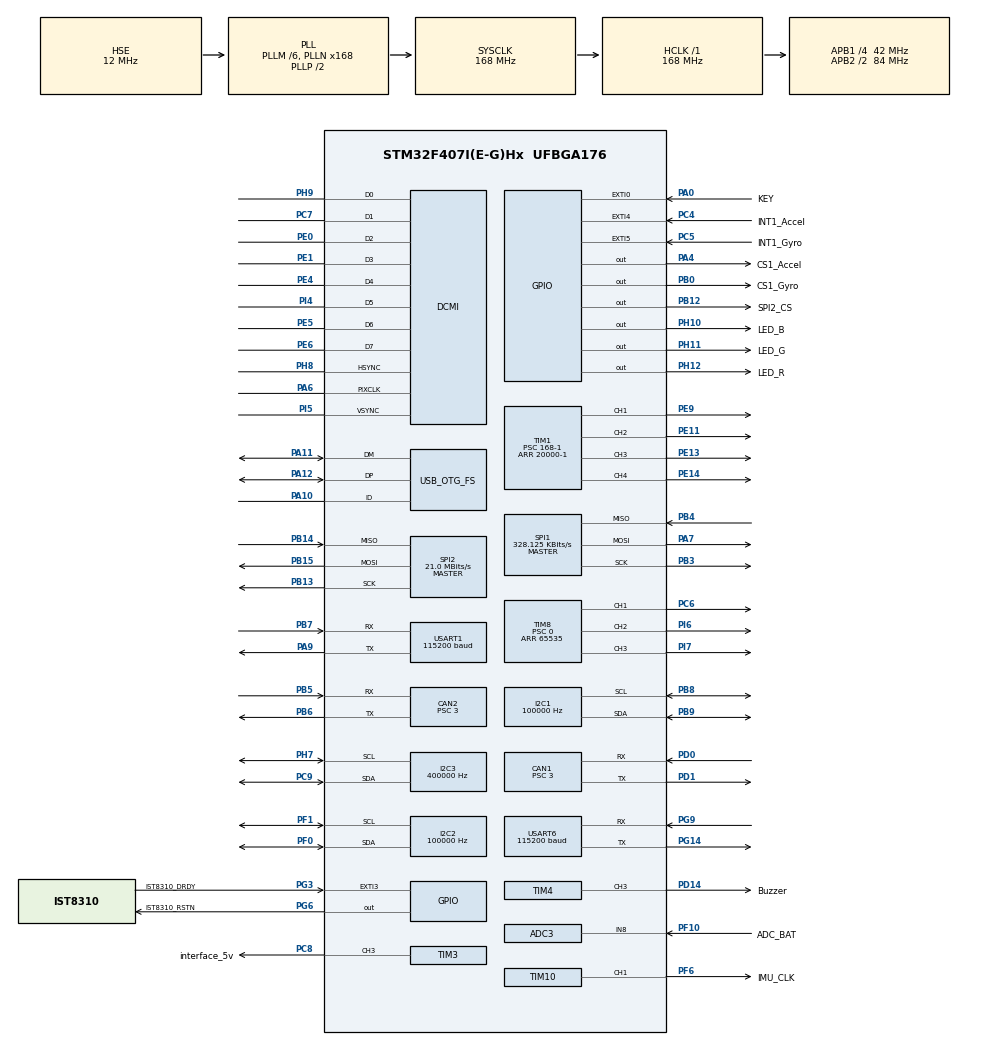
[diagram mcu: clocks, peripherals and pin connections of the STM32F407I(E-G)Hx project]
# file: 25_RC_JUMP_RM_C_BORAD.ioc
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ADC1.Channel-2\#ChannelRegularConversion=ADC_CHANNEL_TEMPSENSOR
ADC1.Channel-IN=ADC_CHANNEL_VREFINT
ADC1.ClockPrescaler=ADC_CLOCK_SYNC_PCLK_DIV4
ADC1.ContinuousConvMode=DISABLE
ADC1.DMAContinuousRequests=DISABLE
ADC1.DataAlign=ADC_DATAALIGN_RIGHT
ADC1.DiscontinuousConvMode=DISABLE
ADC1.EOCSelection=ADC_EOC_SINGLE_CONV
ADC1.EnableAnalogWatchDog=false
ADC1.ExternalTrigConv=ADC_SOFTWARE_START
ADC1.ExternalTrigConvEdge=ADC_EXTERNALTRIGCONVEDGE_NONE
ADC1.InjNumberOfConversion=0
ADC1.Mode=__NULL
ADC1.NbrOfConversion=1
ADC1.Rank-2\#ChannelRegularConversion=1
ADC1.Resolution=ADC_RESOLUTION_12B
ADC1.SamplingTime-2\#ChannelRegularConversion=ADC_SAMPLETIME_3CYCLES
ADC1.ScanConvMode=DISABLE
ADC1.master=1
ADC3.Channel-3\#ChannelRegularConversion=ADC_CHANNEL_8
ADC3.Channel-IN8=ADC_CHANNEL_8
ADC3.ClockPrescaler=ADC_CLOCK_SYNC_PCLK_DIV4
ADC3.ContinuousConvMode=DISABLE
ADC3.DMAContinuousRequests=DISABLE
ADC3.DataAlign=ADC_DATAALIGN_RIGHT
ADC3.DiscontinuousConvMode=DISABLE
ADC3.EOCSelection=ADC_EOC_SINGLE_CONV
ADC3.EnableAnalogWatchDog=false
ADC3.ExternalTrigConv=ADC_SOFTWARE_START
ADC3.ExternalTrigConvEdge=ADC_EXTERNALTRIGCONVEDGE_NONE
ADC3.InjNumberOfConversion=0
ADC3.NbrOfConversion=1
ADC3.Rank-3\#ChannelRegularConversion=1
ADC3.Resolution=ADC_RESOLUTION_12B
ADC3.SamplingTime-3\#ChannelRegularConversion=ADC_SAMPLETIME_3CYCLES
ADC3.ScanConvMode=DISABLE
CAN1.ABOM=DISABLE
CAN1.AWUM=DISABLE
CAN1.BS1=CAN_BS1_10TQ
CAN1.BS2=CAN_BS2_3TQ
CAN1.CalculateBaudRate=1000000
CAN1.CalculateTimeBit=1000
CAN1.CalculateTimeQuantum=71.42857142857143
CAN1.Mode=CAN_MODE_NORMAL
CAN1.NART=DISABLE
CAN1.Prescaler=3
CAN1.RFLM=DISABLE
CAN1.SJW=CAN_SJW_1TQ
CAN1.TTCM=DISABLE
CAN1.TXFP=DISABLE
CAN2.ABOM=DISABLE
CAN2.AWUM=DISABLE
CAN2.BS1=CAN_BS1_10TQ
CAN2.BS2=CAN_BS2_3TQ
CAN2.CalculateBaudRate=1000000
CAN2.CalculateTimeBit=1000
CAN2.CalculateTimeQuantum=71.42857142857143
CAN2.Mode=CAN_MODE_NORMAL
CAN2.NART=DISABLE
CAN2.Prescaler=3
CAN2.RFLM=DISABLE
CAN2.SJW=CAN_SJW_1TQ
CAN2.TTCM=DISABLE
CAN2.TXFP=DISABLE
DCMI.CaptureRate=DCMI_CR_ALL_FRAME
DCMI.HSPolarity=DCMI_HSPOLARITY_LOW
DCMI.JPEGMode=DCMI_JPEG_DISABLE
DCMI.PCKPolarity=DCMI_PCKPOLARITY_FALLING
DCMI.VSPolarity=DCMI_VSPOLARITY_LOW
Dma.Request0=SPI1_RX
Dma.Request1=SPI1_TX
Dma.SPI1_RX.0.Direction=DMA_PERIPH_TO_MEMORY
Dma.SPI1_RX.0.FIFOMode=DMA_FIFOMODE_DISABLE
Dma.SPI1_RX.0.Instance=DMA2_Stream2
Dma.SPI1_RX.0.MemDataAlignment=DMA_MDATAALIGN_BYTE
Dma.SPI1_RX.0.MemInc=DMA_MINC_ENABLE
Dma.SPI1_RX.0.Mode=DMA_NORMAL
Dma.SPI1_RX.0.PeriphDataAlignment=DMA_PDATAALIGN_BYTE
Dma.SPI1_RX.0.PeriphInc=DMA_PINC_DISABLE
Dma.SPI1_RX.0.Priority=DMA_PRIORITY_VERY_HIGH
Dma.SPI1_TX.1.Direction=DMA_MEMORY_TO_PERIPH
Dma.SPI1_TX.1.FIFOMode=DMA_FIFOMODE_DISABLE
Dma.SPI1_TX.1.Instance=DMA2_Stream3
Dma.SPI1_TX.1.MemDataAlignment=DMA_MDATAALIGN_BYTE
Dma.SPI1_TX.1.MemInc=DMA_MINC_ENABLE
Dma.SPI1_TX.1.Mode=DMA_NORMAL
Dma.SPI1_TX.1.PeriphDataAlignment=DMA_PDATAALIGN_BYTE
Dma.SPI1_TX.1.PeriphInc=DMA_PINC_DISABLE
Dma.SPI1_TX.1.Priority=DMA_PRIORITY_HIGH
I2C1.AddressingMode=I2C_ADDRESSINGMODE_7BIT
I2C1.ClockSpeed=100000
I2C1.DualAddressMode=I2C_DUALADDRESS_DISABLE
I2C1.GeneralCallMode=I2C_GENERALCALL_DISABLE
I2C1.I2C_Mode=I2C_Standard
I2C1.NoStretchMode=I2C_NOSTRETCH_DISABLE
I2C1.OwnAddress=0
I2C2.AddressingMode=I2C_ADDRESSINGMODE_7BIT
I2C2.ClockSpeed=100000
I2C2.DualAddressMode=I2C_DUALADDRESS_DISABLE
I2C2.GeneralCallMode=I2C_GENERALCALL_DISABLE
I2C2.I2C_Mode=I2C_Standard
I2C2.NoStretchMode=I2C_NOSTRETCH_DISABLE
I2C2.OwnAddress=0
I2C3.AddressingMode=I2C_ADDRESSINGMODE_7BIT
I2C3.ClockSpeed=400000
I2C3.DualAddressMode=I2C_DUALADDRESS_DISABLE
I2C3.DutyCycle=I2C_DUTYCYCLE_2
I2C3.GeneralCallMode=I2C_GENERALCALL_DISABLE
I2C3.I2C_Mode=I2C_Fast
I2C3.NoStretchMode=I2C_NOSTRETCH_DISABLE
I2C3.OwnAddress=0
Mcu.Family=STM32F4
Mcu.Name=STM32F407I(E-G)Hx
Mcu.Package=UFBGA176
NVIC.CAN1_RX0_IRQn=true\:0\:0\:false\:false\:true\:true\:true\:true
NVIC.CAN1_RX1_IRQn=true\:0\:0\:false\:false\:true\:true\:true\:true
NVIC.DMA2_Stream2_IRQn=true\:0\:0\:false\:false\:true\:false\:true\:true
NVIC.DMA2_Stream3_IRQn=true\:0\:0\:false\:false\:true\:false\:true\:true
NVIC.EXTI0_IRQn=true\:0\:0\:false\:false\:true\:true\:true\:true
NVIC.EXTI3_IRQn=true\:0\:0\:false\:false\:true\:true\:true\:true
NVIC.EXTI4_IRQn=true\:0\:0\:false\:false\:true\:true\:true\:true
NVIC.EXTI9_5_IRQn=true\:0\:0\:false\:false\:true\:true\:true\:true
NVIC.PriorityGroup=NVIC_PRIORITYGROUP_4
PA0-WKUP.GPIO_Label=KEY
PA0-WKUP.GPIO_PuPd=GPIO_PULLUP
PA0-WKUP.Signal=GPXTI0
PA10.Mode=OTG/Dual_Role_Device
PA10.Signal=USB_OTG_FS_ID
PA11.Mode=OTG/Dual_Role_Device
PA11.Signal=USB_OTG_FS_DM
PA12.Mode=OTG/Dual_Role_Device
PA12.Signal=USB_OTG_FS_DP
PA13.Mode=Serial_Wire
PA13.Signal=SYS_JTMS-SWDIO
PA14.Mode=Serial_Wire
PA14.Signal=SYS_JTCK-SWCLK
PA4.GPIO_Label=CS1_Accel
PA4.Signal=GPIO_Output
PA6.Mode=Slave_8_bits_External_Synchro
PA6.Signal=DCMI_PIXCLK
PA7.Mode=Full_Duplex_Master
PA7.Signal=SPI1_MOSI
PA9.Mode=Asynchronous
PA9.Signal=USART1_TX
PB0.GPIO_Label=CS1_Gyro
PB0.Signal=GPIO_Output
PB12.GPIO_Label=SPI2_CS
PB12.Signal=GPIO_Output
PB13.Mode=Full_Duplex_Master
PB13.Signal=SPI2_SCK
PB14.Mode=Full_Duplex_Master
PB14.Signal=SPI2_MISO
PB15.Mode=Full_Duplex_Master
PB15.Signal=SPI2_MOSI
PB3.Mode=Full_Duplex_Master
PB3.Signal=SPI1_SCK
PB4.Mode=Full_Duplex_Master
PB4.Signal=SPI1_MISO
PB5.Mode=CAN_Activate
PB5.Signal=CAN2_RX
PB6.Mode=CAN_Activate
PB6.Signal=CAN2_TX
PB7.Mode=Asynchronous
PB7.Signal=USART1_RX
PB8.Mode=I2C
PB8.Signal=I2C1_SCL
PB9.Mode=I2C
PB9.Signal=I2C1_SDA
PC11.GPIO_Label=DBUS_RX
PC11.Signal=USART3_RX
PC4.GPIO_Label=INT1_Accel
PC4.GPIO_ModeDefaultEXTI=GPIO_MODE_IT_FALLING
PC4.Signal=GPXTI4
PC5.GPIO_Label=INT1_Gyro
PC5.GPIO_ModeDefaultEXTI=GPIO_MODE_IT_FALLING
PC5.Signal=GPXTI5
PC6.Signal=S_TIM8_CH1
PC7.Mode=Slave_8_bits_External_Synchro
PC7.Signal=DCMI_D1
PC8.GPIO_Label=interface_5v
PC8.Signal=S_TIM3_CH3
PC9.Mode=I2C
PC9.Signal=I2C3_SDA
PD0.Mode=CAN_Activate
PD0.Signal=CAN1_RX
PD1.Mode=CAN_Activate
PD1.Signal=CAN1_TX
PD14.GPIO_Label=Buzzer
PD14.Signal=S_TIM4_CH3
PE0.Mode=Slave_8_bits_External_Synchro
PE0.Signal=DCMI_D2
PE1.Mode=Slave_8_bits_External_Synchro
PE1.Signal=DCMI_D3
PE11.Signal=S_TIM1_CH2
PE13.Signal=S_TIM1_CH3
PE14.Signal=S_TIM1_CH4
PE4.Mode=Slave_8_bits_External_Synchro
PE4.Signal=DCMI_D4
PE5.Mode=Slave_8_bits_External_Synchro
PE5.Signal=DCMI_D6
PE6.Mode=Slave_8_bits_External_Synchro
PE6.Signal=DCMI_D7
PE9.Signal=S_TIM1_CH1
PF0.Mode=I2C
PF0.Signal=I2C2_SDA
PF1.Mode=I2C
PF1.Signal=I2C2_SCL
PF10.GPIO_Label=ADC_BAT
PF10.Mode=IN8
PF10.Signal=ADC3_IN8
PF6.GPIO_Label=IMU_CLK
PF6.Signal=S_TIM10_CH1
PG14.Mode=Asynchronous
PG14.Signal=USART6_TX
PG3.GPIO_Label=IST8310_DRDY
PG3.GPIO_ModeDefaultEXTI=GPIO_MODE_IT_FALLING
PG3.GPIO_PuPd=GPIO_PULLUP
PG3.Signal=GPXTI3
PG6.GPIO_Label=IST8310_RSTN
PG6.GPIO_PuPd=GPIO_PULLUP
PG6.GPIO_Speed=GPIO_SPEED_FREQ_MEDIUM
PG6.Signal=GPIO_Output
PG9.Mode=Asynchronous
PG9.Signal=USART6_RX
PH0-OSC_IN.Mode=HSE-External-Oscillator
PH0-OSC_IN.Signal=RCC_OSC_IN
PH1-OSC_OUT.Mode=HSE-External-Oscillator
PH1-OSC_OUT.Signal=RCC_OSC_OUT
PH10.GPIO_Label=LED_B
PH10.GPIO_PuPd=GPIO_NOPULL
PH10.GPIO_Speed=GPIO_SPEED_FREQ_LOW
PH10.Signal=GPIO_Output
PH11.GPIO_Label=LED_G
PH11.Signal=GPIO_Output
PH12.GPIO_Label=LED_R
PH12.Signal=GPIO_Output
PH7.Mode=I2C
PH7.Signal=I2C3_SCL
PH8.Mode=Slave_8_bits_External_Synchro
PH8.Signal=DCMI_HSYNC
PH9.Mode=Slave_8_bits_External_Synchro
PH9.Signal=DCMI_D0
PI4.Mode=Slave_8_bits_External_Synchro
PI4.Signal=DCMI_D5
PI5.Mode=Slave_8_bits_External_Synchro
PI5.Signal=DCMI_VSYNC
PI6.Signal=S_TIM8_CH2
PI7.Signal=S_TIM8_CH3
ProjectManager.HeapSize=0x200
ProjectManager.StackSize=0x400
ProjectManager.TargetToolchain=MDK-ARM V5.32
RCC.48MHZClocksFreq_Value=48000000
RCC.AHBFreq_Value=168000000
RCC.APB1CLKDivider=RCC_HCLK_DIV4
RCC.APB1Freq_Value=42000000
RCC.APB1TimFreq_Value=84000000
RCC.APB2CLKDivider=RCC_HCLK_DIV2
RCC.APB2Freq_Value=84000000
RCC.APB2TimFreq_Value=168000000
RCC.CortexFreq_Value=168000000
RCC.FLatency=FLASH_LATENCY_5
RCC.HCLKFreq_Value=168000000
RCC.HSE_VALUE=12000000
RCC.HSI_VALUE=16000000
RCC.LSE_VALUE=32768
RCC.PLLM=6
RCC.PLLN=168
RCC.PLLQ=7
RCC.SYSCLKFreq_VALUE=168000000
RCC.SYSCLKSource=RCC_SYSCLKSOURCE_PLLCLK
RCC.VCOOutputFreq_Value=336000000
SH.S_TIM10_CH1.0=TIM10_CH1,PWM Generation1 CH1
SH.S_TIM1_CH1.0=TIM1_CH1,PWM Generation1 CH1
SH.S_TIM1_CH2.0=TIM1_CH2,PWM Generation2 CH2
SH.S_TIM1_CH3.0=TIM1_CH3,Forced Output3 CH3
SH.S_TIM1_CH4.0=TIM1_CH4,PWM Generation4 CH4
SH.S_TIM3_CH3.0=TIM3_CH3,PWM Generation3 CH3
SH.S_TIM4_CH3.0=TIM4_CH3,PWM Generation3 CH3
SH.S_TIM8_CH1.0=TIM8_CH1,PWM Generation1 CH1
SH.S_TIM8_CH2.0=TIM8_CH2,PWM Generation2 CH2
SH.S_TIM8_CH3.0=TIM8_CH3,PWM Generation3 CH3
SPI1.BaudRatePrescaler=SPI_BAUDRATEPRESCALER_256
SPI1.CLKPhase=SPI_PHASE_2EDGE
SPI1.CLKPolarity=SPI_POLARITY_LOW
SPI1.CRCCalculation=SPI_CRCCALCULATION_DISABLE
SPI1.CalculateBaudRate=328.125 KBits/s
SPI1.DataSize=SPI_DATASIZE_8BIT
SPI1.Direction=SPI_DIRECTION_2LINES
SPI1.FirstBit=SPI_FIRSTBIT_MSB
SPI1.Mode=SPI_MODE_MASTER
SPI1.NSS=SPI_NSS_SOFT
SPI1.TIMode=SPI_TIMODE_DISABLE
SPI1.VirtualType=VM_MASTER
SPI2.BaudRatePrescaler=SPI_BAUDRATEPRESCALER_2
SPI2.CLKPhase=SPI_PHASE_1EDGE
SPI2.CLKPolarity=SPI_POLARITY_LOW
SPI2.CRCCalculation=SPI_CRCCALCULATION_DISABLE
SPI2.CalculateBaudRate=21.0 MBits/s
SPI2.DataSize=SPI_DATASIZE_8BIT
SPI2.Direction=SPI_DIRECTION_2LINES
SPI2.FirstBit=SPI_FIRSTBIT_MSB
SPI2.Mode=SPI_MODE_MASTER
SPI2.NSS=SPI_NSS_SOFT
SPI2.TIMode=SPI_TIMODE_DISABLE
SPI2.VirtualType=VM_MASTER
TIM1.AutoReloadPreload=TIM_AUTORELOAD_PRELOAD_DISABLE
TIM1.AutomaticOutput=TIM_AUTOMATICOUTPUT_DISABLE
TIM1.BreakPolarity=TIM_BREAKPOLARITY_HIGH
TIM1.BreakState=TIM_BREAK_DISABLE
TIM1.Channel-Forced\ Output3\ CH3=TIM_CHANNEL_3
TIM1.Channel-PWM\ Generation1\ CH1=TIM_CHANNEL_1
TIM1.Channel-PWM\ Generation2\ CH2=TIM_CHANNEL_2
TIM1.Channel-PWM\ Generation4\ CH4=TIM_CHANNEL_4
TIM1.ClockDivision=TIM_CLOCKDIVISION_DIV1
TIM1.CounterMode=TIM_COUNTERMODE_UP
TIM1.LockLevel=TIM_LOCKLEVEL_OFF
TIM1.OC1Preload_PWM=ENABLE
TIM1.OC2Preload_PWM=ENABLE
TIM1.OC3Preload=DISABLE
TIM1.OC4Preload_PWM=ENABLE
TIM1.OCFastMode_PWM-PWM\ Generation1\ CH1=TIM_OCFAST_DISABLE
TIM1.OCFastMode_PWM-PWM\ Generation2\ CH2=TIM_OCFAST_DISABLE
TIM1.OCFastMode_PWM-PWM\ Generation4\ CH4=TIM_OCFAST_DISABLE
TIM1.OCIdleState_1=TIM_OCIDLESTATE_RESET
TIM1.OCIdleState_2=TIM_OCIDLESTATE_RESET
TIM1.OCIdleState_3=TIM_OCIDLESTATE_RESET
TIM1.OCIdleState_4=TIM_OCIDLESTATE_RESET
TIM1.OCMode_PWM-PWM\ Generation1\ CH1=TIM_OCMODE_PWM1
TIM1.OCMode_PWM-PWM\ Generation2\ CH2=TIM_OCMODE_PWM1
TIM1.OCMode_PWM-PWM\ Generation4\ CH4=TIM_OCMODE_PWM1
TIM1.OCMode_forced-Forced\ Output3\ CH3=TIM_OCMODE_FORCED_ACTIVE
TIM1.OCPolarity_1=TIM_OCPOLARITY_HIGH
TIM1.OCPolarity_2=TIM_OCPOLARITY_HIGH
TIM1.OCPolarity_3=TIM_OCPOLARITY_HIGH
TIM1.OCPolarity_4=TIM_OCPOLARITY_HIGH
TIM1.OffStateIDLEMode=TIM_OSSI_DISABLE
TIM1.OffStateRunMode=TIM_OSSR_DISABLE
TIM1.Period=20000-1
TIM1.Prescaler=168-1
TIM1.Pulse-Forced\ Output3\ CH3=0
TIM1.Pulse-PWM\ Generation1\ CH1=0
TIM1.Pulse-PWM\ Generation2\ CH2=0
TIM1.Pulse-PWM\ Generation4\ CH4=0
TIM1.RepetitionCounter=0
TIM1.TIM_MasterOutputTrigger=TIM_TRGO_RESET
TIM1.TIM_MasterSlaveMode=TIM_MASTERSLAVEMODE_DISABLE
TIM10.AutoReloadPreload=TIM_AUTORELOAD_PRELOAD_DISABLE
TIM10.Channel=TIM_CHANNEL_1
TIM10.ClockDivision=TIM_CLOCKDIVISION_DIV1
TIM10.CounterMode=TIM_COUNTERMODE_UP
TIM10.OC1Preload_PWM=ENABLE
TIM10.OCFastMode_PWM=TIM_OCFAST_DISABLE
TIM10.OCMode_PWM=TIM_OCMODE_PWM1
TIM10.OCPolarity_1=TIM_OCPOLARITY_HIGH
TIM10.Period=65535
TIM10.Prescaler=0
TIM10.Pulse=0
TIM3.AutoReloadPreload=TIM_AUTORELOAD_PRELOAD_DISABLE
TIM3.Channel-PWM\ Generation3\ CH3=TIM_CHANNEL_3
TIM3.ClockDivision=TIM_CLOCKDIVISION_DIV1
TIM3.CounterMode=TIM_COUNTERMODE_UP
TIM3.OC3Preload_PWM=ENABLE
TIM3.OCFastMode_PWM-PWM\ Generation3\ CH3=TIM_OCFAST_DISABLE
TIM3.OCMode_PWM-PWM\ Generation3\ CH3=TIM_OCMODE_PWM1
TIM3.OCPolarity_3=TIM_OCPOLARITY_HIGH
TIM3.Period=65535
TIM3.Prescaler=0
TIM3.Pulse-PWM\ Generation3\ CH3=0
TIM3.TIM_MasterOutputTrigger=TIM_TRGO_RESET
TIM3.TIM_MasterSlaveMode=TIM_MASTERSLAVEMODE_DISABLE
TIM4.AutoReloadPreload=TIM_AUTORELOAD_PRELOAD_DISABLE
TIM4.Channel-PWM\ Generation3\ CH3=TIM_CHANNEL_3
TIM4.ClockDivision=TIM_CLOCKDIVISION_DIV1
TIM4.CounterMode=TIM_COUNTERMODE_UP
TIM4.OC3Preload_PWM=ENABLE
TIM4.OCFastMode_PWM-PWM\ Generation3\ CH3=TIM_OCFAST_DISABLE
TIM4.OCMode_PWM-PWM\ Generation3\ CH3=TIM_OCMODE_PWM1
TIM4.OCPolarity_3=TIM_OCPOLARITY_HIGH
TIM4.Period=21000-1
TIM4.Prescaler=0
TIM4.Pulse-PWM\ Generation3\ CH3=0
TIM4.TIM_MasterOutputTrigger=TIM_TRGO_RESET
TIM4.TIM_MasterSlaveMode=TIM_MASTERSLAVEMODE_DISABLE
TIM8.AutoReloadPreload=TIM_AUTORELOAD_PRELOAD_DISABLE
TIM8.AutomaticOutput=TIM_AUTOMATICOUTPUT_DISABLE
TIM8.BreakPolarity=TIM_BREAKPOLARITY_HIGH
TIM8.BreakState=TIM_BREAK_DISABLE
TIM8.Channel-PWM\ Generation1\ CH1=TIM_CHANNEL_1
TIM8.Channel-PWM\ Generation2\ CH2=TIM_CHANNEL_2
TIM8.Channel-PWM\ Generation3\ CH3=TIM_CHANNEL_3
TIM8.ClockDivision=TIM_CLOCKDIVISION_DIV1
TIM8.CounterMode=TIM_COUNTERMODE_UP
TIM8.LockLevel=TIM_LOCKLEVEL_OFF
TIM8.OC1Preload_PWM=ENABLE
TIM8.OC2Preload_PWM=ENABLE
TIM8.OC3Preload_PWM=ENABLE
TIM8.OCFastMode_PWM-PWM\ Generation1\ CH1=TIM_OCFAST_DISABLE
TIM8.OCFastMode_PWM-PWM\ Generation2\ CH2=TIM_OCFAST_DISABLE
TIM8.OCFastMode_PWM-PWM\ Generation3\ CH3=TIM_OCFAST_DISABLE
TIM8.OCIdleState_1=TIM_OCIDLESTATE_RESET
TIM8.OCIdleState_2=TIM_OCIDLESTATE_RESET
TIM8.OCIdleState_3=TIM_OCIDLESTATE_RESET
TIM8.OCMode_PWM-PWM\ Generation1\ CH1=TIM_OCMODE_PWM1
TIM8.OCMode_PWM-PWM\ Generation2\ CH2=TIM_OCMODE_PWM1
TIM8.OCMode_PWM-PWM\ Generation3\ CH3=TIM_OCMODE_PWM1
TIM8.OCPolarity_1=TIM_OCPOLARITY_HIGH
TIM8.OCPolarity_2=TIM_OCPOLARITY_HIGH
TIM8.OCPolarity_3=TIM_OCPOLARITY_HIGH
TIM8.OffStateIDLEMode=TIM_OSSI_DISABLE
TIM8.OffStateRunMode=TIM_OSSR_DISABLE
TIM8.Period=65535
TIM8.Prescaler=0
TIM8.Pulse-PWM\ Generation1\ CH1=0
TIM8.Pulse-PWM\ Generation2\ CH2=0
TIM8.Pulse-PWM\ Generation3\ CH3=0
TIM8.RepetitionCounter=0
TIM8.TIM_MasterOutputTrigger=TIM_TRGO_RESET
TIM8.TIM_MasterSlaveMode=TIM_MASTERSLAVEMODE_DISABLE
USART1.BaudRate=115200
USART1.Mode=MODE_TX_RX
USART1.OverSampling=UART_OVERSAMPLING_16
USART1.Parity=PARITY_NONE
USART1.StopBits=STOPBITS_1
USART1.VirtualMode=VM_ASYNC
USART1.WordLength=WORDLENGTH_8B
USART6.BaudRate=115200
USART6.Mode=MODE_TX_RX
USART6.OverSampling=UART_OVERSAMPLING_16
USART6.Parity=PARITY_NONE
USART6.StopBits=STOPBITS_1
USART6.VirtualMode=VM_ASYNC
USART6.WordLength=WORDLENGTH_8B
VP_ADC1_TempSens_Input.Mode=IN-TempSens
VP_ADC1_Vref_Input.Mode=IN-Vrefint
VP_TIM10_VS_ClockSourceINT.Mode=Enable_Timer
VP_TIM1_VS_ClockSourceINT.Mode=Internal
VP_TIM3_VS_ClockSourceINT.Mode=Internal
VP_TIM4_VS_ClockSourceINT.Mode=Internal
VP_TIM8_VS_ClockSourceINT.Mode=Internal
board=custom

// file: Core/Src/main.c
/* USER CODE BEGIN Header */
/**
  ******************************************************************************
  * @file           : main.c
  * @brief          : Main program body
  ******************************************************************************
  * @attention
  *
  * Copyright (c) 2025 STMicroelectronics.
  * All rights reserved.
  *
  * This software is licensed under terms that can be found in the LICENSE file
  * in the root directory of this software component.
  * If no LICENSE file comes with this software, it is provided AS-IS.
  *
  ******************************************************************************
  */
/* USER CODE END Header */
#include "main.h"
#include "adc.h"
#include "can.h"
#include "dcmi.h"
#include "dma.h"
#include "i2c.h"
#include "spi.h"
#include "tim.h"
#include "usart.h"
#include "usb_otg.h"
#include "gpio.h"

/* USER CODE BEGIN Includes */
#include "c620.h"
/* USER CODE END Includes */

void SystemClock_Config(void);

int main(void)
{

  /* MCU Configuration--------------------------------------------------------*/

  /* Reset of all peripherals, Initializes the Flash interface and the Systick. */
  HAL_Init();

  /* Configure the system clock */
  SystemClock_Config();

  /* Initialize all configured peripherals */
  MX_GPIO_Init();
  MX_DMA_Init();
  MX_CAN1_Init();
  MX_CAN2_Init();
  MX_I2C2_Init();
  MX_I2C3_Init();
  MX_SPI1_Init();
  MX_SPI2_Init();
  MX_TIM1_Init();
  MX_TIM3_Init();
  MX_TIM8_Init();
  MX_TIM10_Init();
  MX_USB_OTG_FS_USB_Init();
  MX_ADC1_Init();
  MX_ADC3_Init();
  MX_DCMI_Init();
  MX_I2C1_Init();
  MX_TIM4_Init();
  MX_USART1_UART_Init();
  MX_USART6_UART_Init();
  /* USER CODE BEGIN 2 */
//	//c620电机组
//	C620_Group_Register(&hcan1,0,0x200);
//	C620_Group_instnce[0]->motor_instnce_1.set.current =  1000;
//  C620_Group_instnce[0]->motor_instnce_1.motor_cofig.motor_enable_flag = MOTOR_ENABLED;
//
//		C620_Group_instnce[0]->motor_instnce_2.set.current =  1000;
//  C620_Group_instnce[0]->motor_instnce_2.motor_cofig.motor_enable_flag = MOTOR_ENABLED;
//					C620_Group_Set_Current(0);
//		HAL_Delay(10);
//dm_j4310电机组

  /* USER CODE END 2 */

  /* Infinite loop */
  while (1)
  {

  }
}

void SystemClock_Config(void)
{
  RCC_OscInitTypeDef RCC_OscInitStruct = {0};
  RCC_ClkInitTypeDef RCC_ClkInitStruct = {0};

  /** Configure the main internal regulator output voltage
  */
  __HAL_RCC_PWR_CLK_ENABLE();
  __HAL_PWR_VOLTAGESCALING_CONFIG(PWR_REGULATOR_VOLTAGE_SCALE1);

  /** Initializes the RCC Oscillators according to the specified parameters
  * in the RCC_OscInitTypeDef structure.
  */
  RCC_OscInitStruct.OscillatorType = RCC_OSCILLATORTYPE_HSE;
  RCC_OscInitStruct.HSEState = RCC_HSE_ON;
  RCC_OscInitStruct.PLL.PLLState = RCC_PLL_ON;
  RCC_OscInitStruct.PLL.PLLSource = RCC_PLLSOURCE_HSE;
  RCC_OscInitStruct.PLL.PLLM = 6;
  RCC_OscInitStruct.PLL.PLLN = 168;
  RCC_OscInitStruct.PLL.PLLP = RCC_PLLP_DIV2;
  RCC_OscInitStruct.PLL.PLLQ = 7;
  if (HAL_RCC_OscConfig(&RCC_OscInitStruct) != HAL_OK)
  {
    Error_Handler();
  }

  /** Initializes the CPU, AHB and APB buses clocks
  */
  RCC_ClkInitStruct.ClockType = RCC_CLOCKTYPE_HCLK|RCC_CLOCKTYPE_SYSCLK
                              |RCC_CLOCKTYPE_PCLK1|RCC_CLOCKTYPE_PCLK2;
  RCC_ClkInitStruct.SYSCLKSource = RCC_SYSCLKSOURCE_PLLCLK;
  RCC_ClkInitStruct.AHBCLKDivider = RCC_SYSCLK_DIV1;
  RCC_ClkInitStruct.APB1CLKDivider = RCC_HCLK_DIV4;
  RCC_ClkInitStruct.APB2CLKDivider = RCC_HCLK_DIV2;

  if (HAL_RCC_ClockConfig(&RCC_ClkInitStruct, FLASH_LATENCY_5) != HAL_OK)
  {
    Error_Handler();
  }
}

void Error_Handler(void)
{
  __disable_irq();
  while (1)
  {
  }
}
